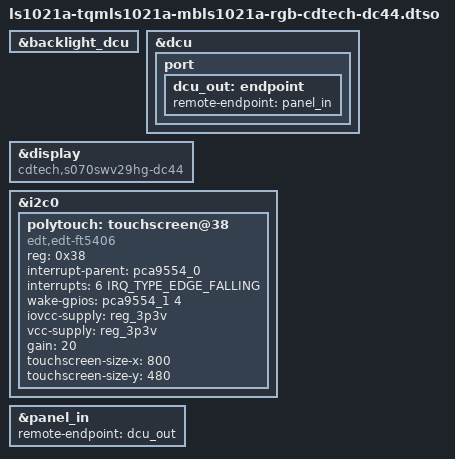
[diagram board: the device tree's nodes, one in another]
// SPDX-License-Identifier: (GPL-2.0-or-later OR MIT)
/*
 * Copyright 2013-2014 Freescale Semiconductor, Inc.
 * Copyright 2018-2025 TQ-Systems GmbH <linux@ew.tq-group.com>,
 * D-82229 Seefeld, Germany.
 * Author: Alexander Stein
 */

#include <dt-bindings/gpio/gpio.h>
#include <dt-bindings/interrupt-controller/irq.h>

/dts-v1/;
/plugin/;

&backlight_dcu {
	status = "okay";
};

&dcu {
	status = "okay";

	port {
		dcu_out: endpoint {
			remote-endpoint = <&panel_in>;
		};
	};
};

&display {
	compatible = "cdtech,s070swv29hg-dc44";
	status = "okay";
};

&i2c0 {
	#address-cells = <1>;
	#size-cells = <0>;

	polytouch: touchscreen@38 {
		compatible = "edt,edt-ft5406";
		reg = <0x38>;
		interrupt-parent = <&pca9554_0>;
		interrupts = <6 IRQ_TYPE_EDGE_FALLING>;
		/* LCD_PWR_EN -> TSC_WAKE */
		wake-gpios = <&pca9554_1 4 GPIO_ACTIVE_HIGH>;
		iovcc-supply = <&reg_3p3v>;
		vcc-supply = <&reg_3p3v>;
		gain = <20>;
		touchscreen-size-x = <800>;
		touchscreen-size-y = <480>;
	};
};

&panel_in {
	remote-endpoint = <&dcu_out>;
};
